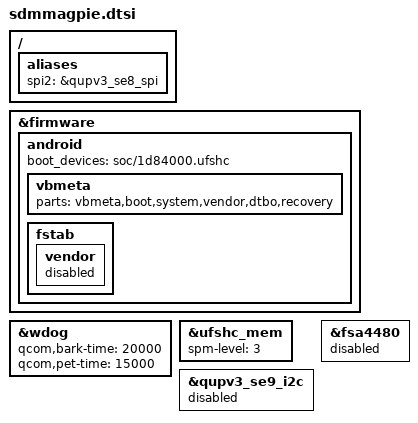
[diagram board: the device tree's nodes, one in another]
/ {
	aliases {
		spi2 = &qupv3_se8_spi;
	};
};

&firmware {
	android {
	        boot_devices = "soc/1d84000.ufshc";
		vbmeta {
			parts = "vbmeta,boot,system,vendor,dtbo,recovery";
		};
		fstab {
			vendor {
				status = "disabled";
			};
		};
	};
};

&wdog {
	qcom,bark-time = <20000>;
	qcom,pet-time = <15000>;
};

&ufshc_mem {
	spm-level = <3>;
};

&qupv3_se9_i2c {
	status = "disabled";
};

&fsa4480 {
	status = "disabled";
};
